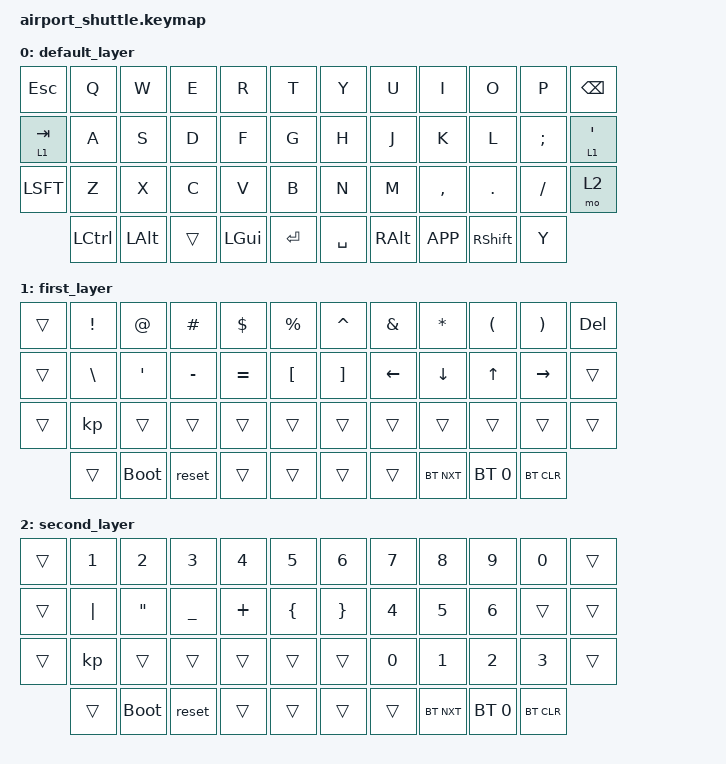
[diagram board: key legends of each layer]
#include <behaviors.dtsi>
#include <dt-bindings/zmk/keys.h>
#include <dt-bindings/zmk/bt.h>

/ {
  keymap {
    compatible = "zmk,keymap";

    default_layer {
// -----------------------------------------------------------------------------------------
// |  ESC  |  Q   |  W   |  E   |  R   |  T   |   Y   |  U    |  I   |  O   |   P   | BSPC  |
// |  TAB  |  A   |  S   |  D   |  F   |  G   |   H   |  J    |  K   |  L   |   ;   |  '    |
// | SHIFT |  Z   |  X   |  C   |  V   |  B   |   N   |  M    |  ,   |  .   |   /   |  RET  |
// | FN    | LGUI | LALT | LCTL | LOWR |     SPACE    |  RAIS | LARW | DARW | UARW  |  RARW |
      bindings = <
  &kp ESC      &kp Q    &kp W &kp E &kp R &kp T  &kp Y   &kp U  &kp I    &kp O   &kp P    &kp BKSP
  &lt 1 TAB &kp A    &kp S &kp D &kp F &kp G  &kp H   &kp J  &kp K    &kp L   &kp SCLN &lt 1 QUOT
  &kp LSFT     &kp Z    &kp X &kp C &kp V &kp B  &kp N   &kp M  &kp CMMA &kp DOT &kp FSLH &mo 2
  &kp LCTL  &kp LALT &trans  &kp LGUI &kp ENTER &kp SPC &kp RALT &kp K_APP &kp RSHFT &kp Y
      >;
    };

    first_layer {
      bindings = <
      &trans &kp EXCL &kp AT &kp HASH &kp DLLR &kp PRCNT &kp CARET &kp AMPS &kp STAR &kp LPAR &kp RPAR &kp DEL
      &trans &kp BSLH &kp SQT &kp MINUS &kp EQUAL &kp LBKT &kp RBKT &kp LEFT &kp DOWN &kp UP &kp RIGHT &trans 
      &trans &kp &trans &trans &trans &trans &trans &trans &trans &trans &trans &trans
      &trans &bootloader &reset &trans &trans &trans &trans &bt BT_NXT &bt BT_SEL 0 &bt BT_CLR
      >;
    };
    second_layer {
      bindings = <
      &trans &kp NUM_1 &kp NUM_2 &kp NUM_3 &kp NUM_4 &kp NUM_5 &kp NUM_6 &kp NUM_7 &kp NUM_8 &kp NUM_9 &kp NUM_0 &trans
      &trans &kp PIPE &kp DQT &kp UNDER &kp PLUS &kp LBRC &kp RBRC &kp N4 &kp N5 &kp N6 &trans &trans 
      &trans &kp &trans &trans &trans &trans &trans &kp N0 &kp N1 &kp N2 &kp N3 &trans
      &trans &bootloader &reset &trans &trans &trans &trans &bt BT_NXT &bt BT_SEL 0 &bt BT_CLR
      >;
    };
  };
};
